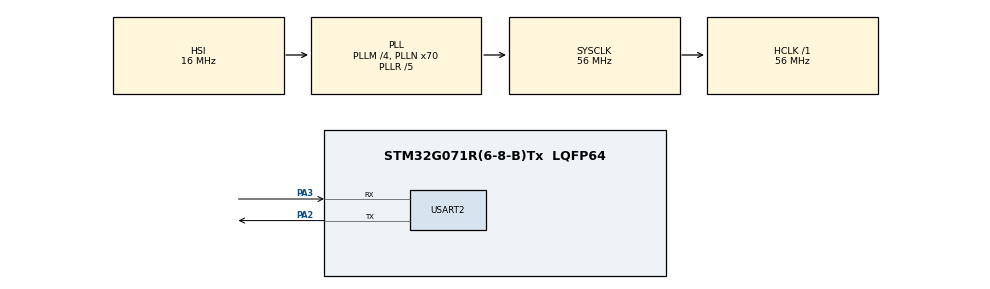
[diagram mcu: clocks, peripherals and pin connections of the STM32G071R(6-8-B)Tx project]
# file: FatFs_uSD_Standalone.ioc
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FATFS.BOARD_NAME=stm32g071rb
FATFS.DISKIO_CODE=1
FATFS._CODE_PAGE=850
FATFS._FS_EXFAT=0
FATFS._FS_LOCK=2
FATFS._FS_MINIMIZE=0
FATFS._FS_NOFSINFO=0
FATFS._FS_NORTC=0
FATFS._FS_READONLY=0
FATFS._FS_REENTRANT=0
FATFS._FS_RPATH=0
FATFS._FS_TIMEOUT=1000
FATFS._FS_TINY=0
FATFS._LFN_UNICODE=0
FATFS._MAX_LFN=255
FATFS._MAX_SS=512
FATFS._MIN_SS=512
FATFS._MULTI_PARTITION=0
FATFS._STRF_ENCODE=3
FATFS._USE_CHMOD=0
FATFS._USE_EXPAND=0
FATFS._USE_FASTSEEK=1
FATFS._USE_FIND=0
FATFS._USE_FORWARD=0
FATFS._USE_LABEL=0
FATFS._USE_LFN=0
FATFS._USE_MKFS=1
FATFS._USE_STRFUNC=0
FATFS._USE_TRIM=0
FATFS._VOLUMES=1
Mcu.Family=STM32G0
Mcu.Name=STM32G071R(6-8-B)Tx
Mcu.Package=LQFP64
PA2.Mode=Asynchronous
PA2.Signal=USART2_TX
PA3.Mode=Asynchronous
PA3.Signal=USART2_RX
ProjectManager.HeapSize=0x400
ProjectManager.StackSize=0x400
ProjectManager.TargetToolchain=EWARM V8.50
RCC.ADCFreq_Value=56000000
RCC.AHBFreq_Value=56000000
RCC.CodegenConfigPeriph=false
RCC.CortexFreq_Value=56000000
RCC.EXTERNAL_CLOCK_VALUE=12288000
RCC.HCLKFreq_Value=56000000
RCC.HSE_VALUE=8000000
RCC.HSI_VALUE=16000000
RCC.LSE_VALUE=32768
RCC.PLLM=RCC_PLLM_DIV4
RCC.PLLN=70
RCC.PLLP=RCC_PLLP_DIV10
RCC.PLLQ=RCC_PLLQ_DIV5
RCC.PLLR=RCC_PLLR_DIV5
RCC.SYSCLKFreq_VALUE=56000000
RCC.SYSCLKSource=RCC_SYSCLKSOURCE_PLLCLK
RCC.VCOOutputFreq_Value=280000000
USART2.Parity=PARITY_ODD
USART2.VirtualMode-Asynchronous=VM_ASYNC
USART2.WordLength=WORDLENGTH_8B
VP_FATFS_VS_Generic.Mode=User_defined
VP_SYS_VS_DBSignals.Mode=DisableDeadBatterySignals
board=custom

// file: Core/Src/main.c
/* USER CODE BEGIN Header */
/**
  ******************************************************************************
  * @file    FatFs/FatFs_uSD_Standalone/Core/Src/main.c
  * @author  MCD Application Team
  * @brief   Main program body
  *          This sample code shows how to use FatFs with uSD card drive.
  ******************************************************************************
  * @attention
  *
  * Copyright (c) 2018-2020 STMicroelectronics.
  * All rights reserved.
  *
  * This software is licensed under terms that can be found in the LICENSE file
  * in the root directory of this software component.
  * If no LICENSE file comes with this software, it is provided AS-IS.
  *
  ******************************************************************************
  */
/* USER CODE END Header */
#include "main.h"
#include "app_fatfs.h"

/* USER CODE BEGIN Includes */
#if defined(__GNUC__)

#include <stdio.h>	/*rtt*/
#include <stdlib.h>	/*rtt*/
extern void initialise_monitor_handles();
#endif

/* USER CODE END Includes */

/* USER CODE BEGIN PM */
#ifdef __GNUC__
/* With GCC, small printf (option LD Linker->Libraries->Small printf
   set to 'Yes') calls __io_putchar() */
#define PUTCHAR_PROTOTYPE int __io_putchar(int ch)
#else
#define PUTCHAR_PROTOTYPE int fputc(int ch, FILE *f)
#endif /* __GNUC__ */
/* USER CODE END PM */

UART_HandleTypeDef huart2;

/* USER CODE BEGIN PV */
__IO int32_t ProcessStatus = 0;
/* USER CODE END PV */

void SystemClock_Config(void);
static void MX_GPIO_Init(void);
static void MX_USART2_UART_Init(void);
/* USER CODE BEGIN PFP */
void Success_Handler(void);
/* USER CODE END PFP */

int main(void)
{
  /* USER CODE BEGIN 1 */

#if defined(__GNUC__)
  initialise_monitor_handles();	/*rtt*/
  printf("Semihosting Test...\n\r");
#endif /* __GNUC__ */

  /* USER CODE END 1 */

  /* MCU Configuration--------------------------------------------------------*/

  /* Reset of all peripherals, Initializes the Flash interface and the Systick. */
  HAL_Init();

  /* Configure the system clock */
  SystemClock_Config();

  /* USER CODE BEGIN SysInit */

  /* Initialize the micro SD Card */
  BSP_SD_Init();
  /* USER CODE END SysInit */

  /* Initialize all configured peripherals */
  MX_GPIO_Init();
  MX_USART2_UART_Init();
  if (MX_FATFS_Init() != APP_OK) {
    Error_Handler();
  }

  /* Infinite loop */
  /* USER CODE BEGIN WHILE */
  while (1)
  {
    ProcessStatus = MX_FATFS_Process();
    /* Call middleware background task */
    if (ProcessStatus == APP_ERROR)
    {
      Error_Handler();
    }
    else if (ProcessStatus == APP_OK)
    {
      Success_Handler();
    }

    /* USER CODE END WHILE */

  }
}

void SystemClock_Config(void)
{
  RCC_OscInitTypeDef RCC_OscInitStruct = {0};
  RCC_ClkInitTypeDef RCC_ClkInitStruct = {0};

  /** Configure the main internal regulator output voltage
  */
  HAL_PWREx_ControlVoltageScaling(PWR_REGULATOR_VOLTAGE_SCALE1);

  /** Initializes the RCC Oscillators according to the specified parameters
  * in the RCC_OscInitTypeDef structure.
  */
  RCC_OscInitStruct.OscillatorType = RCC_OSCILLATORTYPE_HSI;
  RCC_OscInitStruct.HSIState = RCC_HSI_ON;
  RCC_OscInitStruct.HSIDiv = RCC_HSI_DIV1;
  RCC_OscInitStruct.HSICalibrationValue = RCC_HSICALIBRATION_DEFAULT;
  RCC_OscInitStruct.PLL.PLLState = RCC_PLL_ON;
  RCC_OscInitStruct.PLL.PLLSource = RCC_PLLSOURCE_HSI;
  RCC_OscInitStruct.PLL.PLLM = RCC_PLLM_DIV4;
  RCC_OscInitStruct.PLL.PLLN = 70;
  RCC_OscInitStruct.PLL.PLLP = RCC_PLLP_DIV10;
  RCC_OscInitStruct.PLL.PLLQ = RCC_PLLQ_DIV5;
  RCC_OscInitStruct.PLL.PLLR = RCC_PLLR_DIV5;
  if (HAL_RCC_OscConfig(&RCC_OscInitStruct) != HAL_OK)
  {
    Error_Handler();
  }

  /** Initializes the CPU, AHB and APB buses clocks
  */
  RCC_ClkInitStruct.ClockType = RCC_CLOCKTYPE_HCLK|RCC_CLOCKTYPE_SYSCLK
                              |RCC_CLOCKTYPE_PCLK1;
  RCC_ClkInitStruct.SYSCLKSource = RCC_SYSCLKSOURCE_PLLCLK;
  RCC_ClkInitStruct.AHBCLKDivider = RCC_SYSCLK_DIV1;
  RCC_ClkInitStruct.APB1CLKDivider = RCC_HCLK_DIV1;

  if (HAL_RCC_ClockConfig(&RCC_ClkInitStruct, FLASH_LATENCY_2) != HAL_OK)
  {
    Error_Handler();
  }
}

static void MX_USART2_UART_Init(void)
{

  huart2.Instance = USART2;
  huart2.Init.BaudRate = 115200;
  huart2.Init.WordLength = UART_WORDLENGTH_8B;
  huart2.Init.StopBits = UART_STOPBITS_1;
  huart2.Init.Parity = UART_PARITY_ODD;
  huart2.Init.Mode = UART_MODE_TX_RX;
  huart2.Init.HwFlowCtl = UART_HWCONTROL_NONE;
  huart2.Init.OverSampling = UART_OVERSAMPLING_16;
  huart2.Init.OneBitSampling = UART_ONE_BIT_SAMPLE_DISABLE;
  huart2.Init.ClockPrescaler = UART_PRESCALER_DIV1;
  huart2.AdvancedInit.AdvFeatureInit = UART_ADVFEATURE_NO_INIT;
  if (HAL_UART_Init(&huart2) != HAL_OK)
  {
    Error_Handler();
  }
  if (HAL_UARTEx_SetTxFifoThreshold(&huart2, UART_TXFIFO_THRESHOLD_1_8) != HAL_OK)
  {
    Error_Handler();
  }
  if (HAL_UARTEx_SetRxFifoThreshold(&huart2, UART_RXFIFO_THRESHOLD_1_8) != HAL_OK)
  {
    Error_Handler();
  }
  if (HAL_UARTEx_DisableFifoMode(&huart2) != HAL_OK)
  {
    Error_Handler();
  }

}

static void MX_GPIO_Init(void)
{

  /* GPIO Ports Clock Enable */
  __HAL_RCC_GPIOA_CLK_ENABLE();

}

/* USER CODE BEGIN 4 */
/**
  * @brief  Retargets the C library printf function to the USART.
  * @param  None
  * @retval None
  */
PUTCHAR_PROTOTYPE
{
  /* Place your implementation of fputc here */
  /* e.g. write a character to the USART1 and Loop until the end of transmission */
  HAL_UART_Transmit(&huart2, (uint8_t *)&ch, 1, 0xFFFF);

  return ch;
}

/**
  * @brief  This function is executed in case of success.
  * @retval None
  */
void Success_Handler(void)
{
  printf("** Success. ** \n\r");
  while(1)
  {
  }
}
/* USER CODE END 4 */

void Error_Handler(void)
{
  /* USER CODE BEGIN Error_Handler_Debug */
  /* User can add his own implementation to report the HAL error return state */
  printf("** Error. ** \n\r");
  while(1)
  {
  }
  /* USER CODE END Error_Handler_Debug */
}
